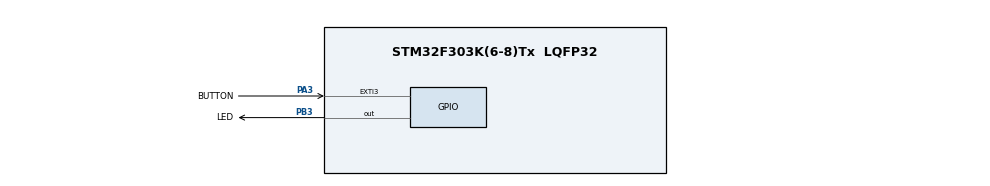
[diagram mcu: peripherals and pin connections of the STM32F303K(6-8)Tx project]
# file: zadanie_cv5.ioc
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Mcu.Family=STM32F3
Mcu.Name=STM32F303K(6-8)Tx
Mcu.Package=LQFP32
NVIC.EXTI3_IRQn=true\:0\:0\:false\:false\:true\:true\:true
NVIC.PriorityGroup=NVIC_PRIORITYGROUP_4
PA3.GPIO_Label=BUTTON
PA3.GPIO_PuPd=GPIO_PULLUP
PA3.Signal=GPXTI3
PB3.GPIO_Label=LED
PB3.GPIO_ModeDefaultOutputPP=GPIO_MODE_OUTPUT_PP
PB3.Signal=GPIO_Output
ProjectManager.HeapSize=0x200
ProjectManager.StackSize=0x400
ProjectManager.TargetToolchain=STM32CubeIDE
RCC.AHBFreq_Value=8000000
RCC.APB1Freq_Value=8000000
RCC.APB2Freq_Value=8000000
RCC.CortexFreq_Value=8000000
RCC.HSE_VALUE=8000000
RCC.HSI_VALUE=8000000
RCC.SYSCLKFreq_VALUE=8000000
board=custom

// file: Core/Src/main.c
/* USER CODE BEGIN Header */
/**
  ******************************************************************************
  * @file           : main.c
  * @brief          : Main program body
  ******************************************************************************
  * @attention
  *
  * <h2><center>&copy; Copyright (c) 2020 STMicroelectronics.
  * All rights reserved.</center></h2>
  *
  * This software component is licensed by ST under BSD 3-Clause license,
  * the "License"; You may not use this file except in compliance with the
  * License. You may obtain a copy of the License at:
  *                        opensource.org/licenses/BSD-3-Clause
  *
  ******************************************************************************
  */
/* USER CODE END Header */
#include "main.h"
#include "gpio.h"

void SystemClock_Config(void);
uint8_t check_button_state(GPIO_TypeDef* PORT, uint8_t PIN);

int main(void)
{

  /* MCU Configuration--------------------------------------------------------*/

  /* Reset of all peripherals, Initializes the Flash interface and the Systick. */

  LL_APB2_GRP1_EnableClock(LL_APB2_GRP1_PERIPH_SYSCFG);
  LL_APB1_GRP1_EnableClock(LL_APB1_GRP1_PERIPH_PWR);

  NVIC_SetPriorityGrouping(NVIC_PRIORITYGROUP_4);

  /* System interrupt init*/

  /* Configure the system clock */
  SystemClock_Config();

  /* Initialize all configured peripherals */
  MX_GPIO_Init();

  /* Infinite loop */
  while (1)
  {
	  if(switch_state)
	  	  {
	  		  LL_GPIO_SetOutputPin(GPIO_PORT_LED, GPIO_PIN_LED);
	  		  for(uint16_t i=0; i<0xFF00; i++){}
	  		  LL_GPIO_ResetOutputPin(GPIO_PORT_LED, GPIO_PIN_LED);
	  		  for(uint16_t i=0; i<0xFF00; i++){}
	  	  }
	  	  else
	  	  {
	  		  LL_GPIO_ResetOutputPin(GPIO_PORT_LED, GPIO_PIN_LED);
	  	  }
  }
}

void SystemClock_Config(void)
{
  LL_FLASH_SetLatency(LL_FLASH_LATENCY_0);
  while(LL_FLASH_GetLatency()!= LL_FLASH_LATENCY_0)
  {
  }
  LL_RCC_HSI_Enable();

   /* Wait till HSI is ready */
  while(LL_RCC_HSI_IsReady() != 1)
  {

  }
  LL_RCC_HSI_SetCalibTrimming(16);
  LL_RCC_SetAHBPrescaler(LL_RCC_SYSCLK_DIV_1);
  LL_RCC_SetAPB1Prescaler(LL_RCC_APB1_DIV_1);
  LL_RCC_SetAPB2Prescaler(LL_RCC_APB1_DIV_1);
  LL_RCC_SetSysClkSource(LL_RCC_SYS_CLKSOURCE_HSI);

   /* Wait till System clock is ready */
  while(LL_RCC_GetSysClkSource() != LL_RCC_SYS_CLKSOURCE_STATUS_HSI)
  {

  }
  LL_Init1msTick(8000000);
  LL_SetSystemCoreClock(8000000);
}

/* USER CODE BEGIN 4 */
uint8_t checkButtonState(GPIO_TypeDef* PORT, uint8_t PIN, uint8_t edge, uint8_t samples_window, uint8_t samples_required)
{
	  //type your code for "checkButtonState" implementation here:

	/*
	(\____/)
	(͡ ͡°͜ ʖ ͡ ͡°) your code for "checkButtonState" implementation here:
	 \╭�?�             \╭�?�
	*/

	uint8_t cnt = 0; // counts samples in row
	for(; samples_window > 0 ; samples_window--){
		if( edge ^ LL_GPIO_IsInputPinSet(GPIO_PORT_BUTTON, GPIO_PIN_BUTTON))
			cnt++;
		else
			cnt = 0;

		if(cnt >= samples_required)
			return 1;
	}
	return 0;
}
/* USER CODE END 4 */

void Error_Handler(void)
{
}

/************************ (C) COPYRIGHT STMicroelectronics *****END OF FILE****/
